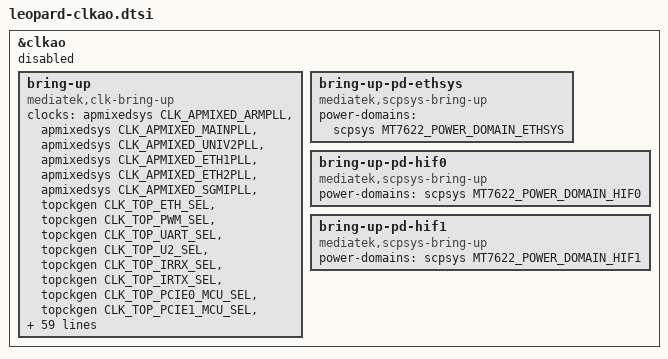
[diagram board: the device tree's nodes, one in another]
/*
 * Copyright (c) 2018 MediaTek Inc.
 * Author: Wenzhen.Yu <Wenzhen.Yu@mediatek.com>
 *
 * This program is free software; you can redistribute it and/or modify
 * it under the terms of the GNU General Public License version 2 as
 * published by the Free Software Foundation.
 *
 * This program is distributed in the hope that it will be useful,
 * but WITHOUT ANY WARRANTY; without even the implied warranty of
 * MERCHANTABILITY or FITNESS FOR A PARTICULAR PURPOSE.  See the
 * GNU General Public License for more details.
 */

&clkao {
	status = "disabled";

	bring-up {
		compatible = "mediatek,clk-bring-up";
		clocks =
			<&apmixedsys CLK_APMIXED_ARMPLL>,
			<&apmixedsys CLK_APMIXED_MAINPLL>,
			<&apmixedsys CLK_APMIXED_UNIV2PLL>,
			<&apmixedsys CLK_APMIXED_ETH1PLL>,
			<&apmixedsys CLK_APMIXED_ETH2PLL>,
			<&apmixedsys CLK_APMIXED_SGMIPLL>,
			<&topckgen CLK_TOP_ETH_SEL>,
			<&topckgen CLK_TOP_PWM_SEL>,
			<&topckgen CLK_TOP_UART_SEL>,
			<&topckgen CLK_TOP_U2_SEL>,
			<&topckgen CLK_TOP_IRRX_SEL>,
			<&topckgen CLK_TOP_IRTX_SEL>,
			<&topckgen CLK_TOP_PCIE0_MCU_SEL>,
			<&topckgen CLK_TOP_PCIE1_MCU_SEL>,
			<&topckgen CLK_TOP_SSUSB_MCU_SEL>,
			<&topckgen CLK_TOP_SGMII_REF_1_SEL>,
			<&topckgen CLK_TOP_10M_SEL>,
			<&infracfg CLK_INFRA_DBGCLK_PD>,
			<&infracfg CLK_INFRA_TRNG_PD>,
			<&infracfg CLK_INFRA_DEVAPC_PD>,
			<&infracfg CLK_INFRA_APXGPT_PD>,
			<&infracfg CLK_INFRA_SEJ_PD>,
			<&pericfg CLK_PERI_PWM1_PD>,
			<&pericfg CLK_PERI_PWM2_PD>,
			<&pericfg CLK_PERI_PWM3_PD>,
			<&pericfg CLK_PERI_PWM4_PD>,
			<&pericfg CLK_PERI_PWM5_PD>,
			<&pericfg CLK_PERI_PWM6_PD>,
			<&pericfg CLK_PERI_PWM7_PD>,
			<&pericfg CLK_PERI_PWM_PD>,
			<&pericfg CLK_PERI_AP_DMA_PD>,
			<&pericfg CLK_PERI_MSDC30_1_PD>,
			<&pericfg CLK_PERI_UART0_PD>,
			<&pericfg CLK_PERI_UART1_PD>,
			<&pericfg CLK_PERI_UART2_PD>,
			<&pericfg CLK_PERI_UART3_PD>,
			<&pericfg CLK_PERI_BTIF_PD>,
			<&pericfg CLK_PERI_I2C0_PD>,
			<&pericfg CLK_PERI_SPI0_PD>,
			<&pericfg CLK_PERI_SNFI_PD>,
			<&pericfg CLK_PERI_NFI_PD>,
			<&pericfg CLK_PERI_NFIECC_PD>,
			<&pericfg CLK_PERI_FLASH_PD>,
			<&ssusbsys CLK_SSUSB_U2_PHY_1P_EN>,
			<&ssusbsys CLK_SSUSB_U2_PHY_EN>,
			<&ssusbsys CLK_SSUSB_REF_EN>,
			<&ssusbsys CLK_SSUSB_SYS_EN>,
			<&ssusbsys CLK_SSUSB_MCU_EN>,
			<&ssusbsys CLK_SSUSB_DMA_EN>,
			<&pciesys CLK_PCIE_P1_AUX_EN>,
			<&pciesys CLK_PCIE_P1_OBFF_EN>,
			<&pciesys CLK_PCIE_P1_AHB_EN>,
			<&pciesys CLK_PCIE_P1_AXI_EN>,
			<&pciesys CLK_PCIE_P1_MAC_EN>,
			<&pciesys CLK_PCIE_P1_PIPE_EN>,
			<&pciesys CLK_PCIE_P0_AUX_EN>,
			<&pciesys CLK_PCIE_P0_OBFF_EN>,
			<&pciesys CLK_PCIE_P0_AHB_EN>,
			<&pciesys CLK_PCIE_P0_AXI_EN>,
			<&pciesys CLK_PCIE_P0_MAC_EN>,
			<&pciesys CLK_PCIE_P0_PIPE_EN>,
			<&ethsys CLK_ETH_FE_EN>,
			<&ethsys CLK_ETH_GP2_EN>,
			<&ethsys CLK_ETH_GP1_EN>,
			<&ethsys CLK_ETH_GP0_EN>,
			<&ethsys CLK_ETH_ESW_EN>,
			<&sgmiisys_0 CLK_SGMII0_TX_EN>,
			<&sgmiisys_0 CLK_SGMII0_RX_EN>,
			<&sgmiisys_0 CLK_SGMII0_CDR_REF>,
			<&sgmiisys_0 CLK_SGMII0_CDR_FB>,
			<&sgmiisys_1 CLK_SGMII1_TX_EN>,
			<&sgmiisys_1 CLK_SGMII1_RX_EN>,
			<&sgmiisys_1 CLK_SGMII1_CDR_REF>,
			<&sgmiisys_1 CLK_SGMII1_CDR_FB>;

		clock-names = "0", "1", "2", "3", "4", "5", "6", "7", "8", "9", "10", "11",
		"12", "13", "14", "15", "16", "17", "18", "19", "20", "21", "22", "23",
		"24", "25", "26", "27", "28", "29", "30", "31", "32", "33", "34", "35",
		"36", "37", "38", "39", "40", "41", "42", "43", "44", "45", "46", "47",
		"48", "49", "50", "51", "52", "53", "54", "55", "56", "57", "58", "59",
		"60", "61", "62", "63", "64", "65", "66", "67", "68", "69", "70", "71",
		"72", "73";
	};

	bring-up-pd-ethsys {
		compatible = "mediatek,scpsys-bring-up";
		power-domains = <&scpsys MT7622_POWER_DOMAIN_ETHSYS>;
	};

	bring-up-pd-hif0 {
		compatible = "mediatek,scpsys-bring-up";
		power-domains = <&scpsys MT7622_POWER_DOMAIN_HIF0>;
	};

	bring-up-pd-hif1 {
		compatible = "mediatek,scpsys-bring-up";
		power-domains = <&scpsys MT7622_POWER_DOMAIN_HIF1>;
	};
};
